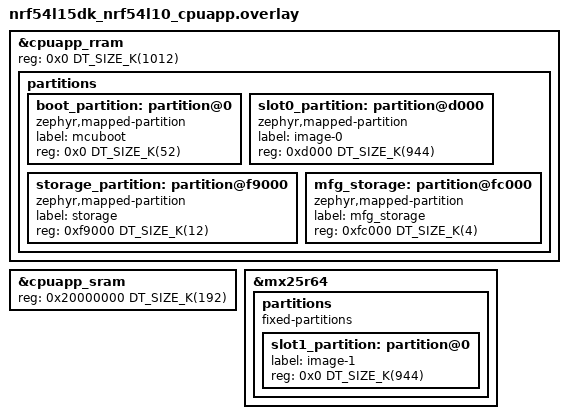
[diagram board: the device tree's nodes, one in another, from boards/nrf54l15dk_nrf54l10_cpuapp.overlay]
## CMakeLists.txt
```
#
# Copyright (c) 2023 Nordic Semiconductor ASA
#
# SPDX-License-Identifier: LicenseRef-Nordic-5-Clause
#

cmake_minimum_required(VERSION 3.20.0)

find_package(Zephyr REQUIRED HINTS $ENV{ZEPHYR_BASE})
project(simple_bootloader)

target_sources(app PRIVATE
  src/main.c
)
```

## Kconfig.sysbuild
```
#
# Copyright (c) 2023 Nordic Semiconductor ASA
#
# SPDX-License-Identifier: LicenseRef-Nordic-5-Clause
#

choice BOOTLOADER
	default BOOTLOADER_MCUBOOT
endchoice

if BOOTLOADER_MCUBOOT

choice MCUBOOT_MODE
	default MCUBOOT_MODE_OVERWRITE_ONLY
endchoice

config DFU_MULTI_IMAGE_PACKAGE_BUILD
	default y

config DFU_MULTI_IMAGE_PACKAGE_APP
	default y

config MERGED_HEX_FILES
	default y

endif # BOOTLOADER_MCUBOOT

source "${ZEPHYR_BASE}/share/sysbuild/Kconfig"
```

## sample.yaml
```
sample:
  name: simple bootloader app
  description: Small footprint application to verify sidewalk dfu
tests:
  sidewalk.test.simple_bootloader:
    sysbuild: true
    build_only: true
    platform_allow:
      - nrf52840dk/nrf52840
      - nrf54l15dk/nrf54l15/cpuapp
      - nrf54l15dk/nrf54l15/cpuapp/ns
      - nrf54l15dk/nrf54l10/cpuapp
    integration_platforms:
      - nrf52840dk/nrf52840
      - nrf54l15dk/nrf54l15/cpuapp
      - nrf54l15dk/nrf54l15/cpuapp/ns
      - nrf54l15dk/nrf54l10/cpuapp
    tags: Sidewalk
```

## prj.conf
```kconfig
#
# Copyright (c) 2023 Nordic Semiconductor ASA
#
# SPDX-License-Identifier: LicenseRef-Nordic-5-Clause
#

CONFIG_BOOTLOADER_MCUBOOT=y
CONFIG_LOG=y
CONFIG_DK_LIBRARY=y
```

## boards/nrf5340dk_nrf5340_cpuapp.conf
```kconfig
#
# Copyright (c) 2023 Nordic Semiconductor ASA
#
# SPDX-License-Identifier: LicenseRef-Nordic-5-Clause
#

CONFIG_BOARD_ENABLE_CPUNET=y
```

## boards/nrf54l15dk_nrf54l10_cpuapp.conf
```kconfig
#
# Copyright (c) 2024 Nordic Semiconductor ASA
#
# SPDX-License-Identifier: LicenseRef-Nordic-5-Clause
#

CONFIG_POWEROFF=y

# nRF54L15DK uses SPI NOR external flash for DFU
CONFIG_FLASH=y
CONFIG_SPI=y
CONFIG_SPI_NOR=y
CONFIG_MULTITHREADING=y
CONFIG_PM_OVERRIDE_EXTERNAL_DRIVER_CHECK=y
CONFIG_MCUMGR_GRP_IMG_ALLOW_ERASE_PENDING=y
```

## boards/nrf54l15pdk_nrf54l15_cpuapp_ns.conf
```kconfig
#
# Copyright (c) 2024 Nordic Semiconductor ASA
#
# SPDX-License-Identifier: LicenseRef-Nordic-5-Clause
#

# Multirole is the only currently supported role by SoftDevice.
CONFIG_BT_LL_SOFTDEVICE_MULTIROLE=y

CONFIG_FPROTECT=n
CONFIG_PM=n
CONFIG_HWINFO_NRF=n
```

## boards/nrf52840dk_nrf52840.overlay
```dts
/*
 * Copyright (c) 2023 Nordic Semiconductor ASA
 *
 * SPDX-License-Identifier: LicenseRef-Nordic-5-Clause
 */


#include <nrf52840_partitions.dtsi>
```

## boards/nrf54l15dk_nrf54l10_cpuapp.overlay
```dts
/*
 * Copyright (c) 2024 Nordic Semiconductor ASA
 *
 * SPDX-License-Identifier: LicenseRef-Nordic-5-Clause
 */

&cpuapp_rram {
	reg = <0x0 DT_SIZE_K(1012)>;
};

&cpuapp_sram {
	reg = <0x20000000 DT_SIZE_K(192)>;
	ranges = <0x0 0x20000000 DT_SIZE_K(192)>;
};

&mx25r64 {
	status = "okay";
};

/delete-node/ &boot_partition;
/delete-node/ &slot0_partition;
/delete-node/ &slot1_partition;
/delete-node/ &storage_partition;

&cpuapp_rram {
	partitions {
		ranges;
		#address-cells = <1>;
		#size-cells = <1>;

		boot_partition: partition@0 {
			compatible = "zephyr,mapped-partition";
			label = "mcuboot";
			reg = <0x0 DT_SIZE_K(52)>;
		};

		slot0_partition: partition@d000 {
			compatible = "zephyr,mapped-partition";
			label = "image-0";
			reg = <0xd000 DT_SIZE_K(944)>;
		};

		storage_partition: partition@f9000 {
			compatible = "zephyr,mapped-partition";
			label = "storage";
			reg = <0xf9000 DT_SIZE_K(12)>;
		};

		mfg_storage: partition@fc000 {
			compatible = "zephyr,mapped-partition";
			label = "mfg_storage";
			reg = <0xfc000 DT_SIZE_K(4)>;
		};
	};
};

&mx25r64 {
	partitions {
		compatible = "fixed-partitions";
		#address-cells = <1>;
		#size-cells = <1>;

		slot1_partition: partition@0 {
			label = "image-1";
			reg = <0x0 DT_SIZE_K(944)>;
		};
	};
};
```

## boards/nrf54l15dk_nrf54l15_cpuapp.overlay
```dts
/*
 * Copyright (c) 2024 Nordic Semiconductor ASA
 *
 * SPDX-License-Identifier: LicenseRef-Nordic-5-Clause
 */

#include <nrf54l15_cpuapp_partitions.dtsi>
```

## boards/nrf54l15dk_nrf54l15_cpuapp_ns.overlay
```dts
/*
 * Copyright (c) 2026 Nordic Semiconductor ASA
 *
 * SPDX-License-Identifier: LicenseRef-Nordic-5-Clause
 */

#include <nrf54l15_cpuapp_memory.dtsi>

&sram0_s {
	reg = <0x0 0x13000>;
	ranges = <0x0 0x0 0x13000>;
};

&sram0_ns {
	reg = <0x13000 0x2d000>;
	ranges = <0x0 0x13000 0x2d000>;
};

#include <nrf54l15_cpuapp_ns_partitions.dtsi>
```

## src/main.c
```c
/*
 * Copyright (c) 2023 Nordic Semiconductor ASA
 *
 * SPDX-License-Identifier: LicenseRef-Nordic-5-Clause
 */

#include <dk_buttons_and_leds.h>
#include <zephyr/logging/log.h>
LOG_MODULE_REGISTER(main, LOG_LEVEL_DBG);

int main(void)
{
	LOG_INF("Hello world!");

	dk_leds_init();
	dk_set_led_on(DK_LED1);

	return 0;
}
```
